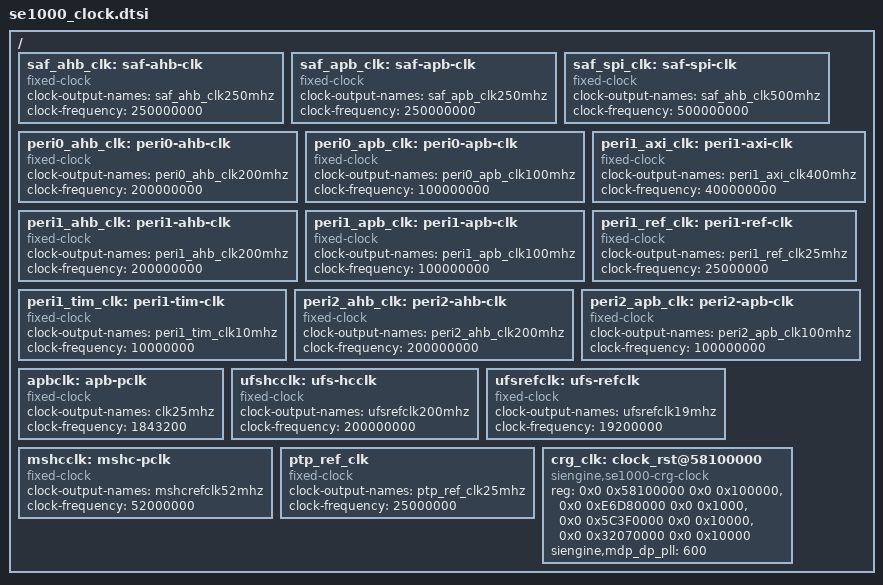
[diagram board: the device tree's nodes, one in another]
/ {
	saf_ahb_clk: saf-ahb-clk {
		clock-output-names = "saf_ahb_clk250mhz";
		clock-frequency = <250000000>;
		#clock-cells = <0x0>;
		compatible = "fixed-clock";
	};

	saf_apb_clk: saf-apb-clk {
		clock-output-names = "saf_apb_clk250mhz";
		clock-frequency = <250000000>;
		#clock-cells = <0x0>;
		compatible = "fixed-clock";
	};

	saf_spi_clk: saf-spi-clk {
		clock-output-names = "saf_ahb_clk500mhz";
		clock-frequency = <500000000>;
		#clock-cells = <0x0>;
		compatible = "fixed-clock";
	};

	peri0_ahb_clk: peri0-ahb-clk {
		clock-output-names = "peri0_ahb_clk200mhz";
		clock-frequency = <200000000>;
		#clock-cells = <0x0>;
		compatible = "fixed-clock";
	};

	peri0_apb_clk: peri0-apb-clk {
		clock-output-names = "peri0_apb_clk100mhz";
		clock-frequency = <100000000>;
		#clock-cells = <0x0>;
		compatible = "fixed-clock";
	};

	peri1_axi_clk: peri1-axi-clk {
		clock-output-names = "peri1_axi_clk400mhz";
		clock-frequency = <400000000>;
		#clock-cells = <0x0>;
		compatible = "fixed-clock";
	};

	peri1_ahb_clk: peri1-ahb-clk {
		clock-output-names = "peri1_ahb_clk200mhz";
		clock-frequency = <200000000>;
		#clock-cells = <0x0>;
		compatible = "fixed-clock";
	};

	peri1_apb_clk: peri1-apb-clk {
		clock-output-names = "peri1_apb_clk100mhz";
		clock-frequency = <100000000>;
		#clock-cells = <0x0>;
		compatible = "fixed-clock";
	};

	peri1_ref_clk: peri1-ref-clk {
		clock-output-names = "peri1_ref_clk25mhz";
		clock-frequency = <25000000>;
		#clock-cells = <0x0>;
		compatible = "fixed-clock";
	};

	peri1_tim_clk: peri1-tim-clk {
		clock-output-names = "peri1_tim_clk10mhz";
		clock-frequency = <10000000>;
		#clock-cells = <0x0>;
		compatible = "fixed-clock";
	};

	peri2_ahb_clk: peri2-ahb-clk {
		clock-output-names = "peri2_ahb_clk200mhz";
		clock-frequency = <200000000>;
		#clock-cells = <0x0>;
		compatible = "fixed-clock";
	};

	peri2_apb_clk: peri2-apb-clk {
		clock-output-names = "peri2_apb_clk100mhz";
		clock-frequency = <100000000>;
		#clock-cells = <0x0>;
		compatible = "fixed-clock";
	};

	apbclk: apb-pclk {
		clock-output-names = "clk25mhz";
		clock-frequency = <1843200>;
		#clock-cells = <0x0>;
		compatible = "fixed-clock";
	};

	ufshcclk: ufs-hcclk {
		clock-output-names = "ufsrefclk200mhz";
		clock-frequency = <200000000>;
		#clock-cells = <0x0>;
		compatible = "fixed-clock";
	};

	ufsrefclk: ufs-refclk {
		clock-output-names = "ufsrefclk19mhz";
		clock-frequency = <19200000>;
		#clock-cells = <0x0>;
		compatible = "fixed-clock";
	};

	mshcclk: mshc-pclk {
		clock-output-names = "mshcrefclk52mhz";
		clock-frequency = <52000000>;
		#clock-cells = <0x0>;
		compatible = "fixed-clock";
	};

	ptp_ref_clk: ptp_ref_clk {
		clock-output-names = "ptp_ref_clk25mhz";
		clock-frequency = <25000000>;
		#clock-cells = <0x0>;
		compatible = "fixed-clock";
	};

	crg_clk: clock_rst@58100000 {
		compatible = "siengine,se1000-crg-clock";
		#clock-cells = <1>;
		#reset-cells = <1>;
		reg = <0x0 0x58100000 0x0 0x100000>,
			<0x0 0xE6D80000 0x0 0x1000>,/* mdp misc*/
			<0x0 0x5C3F0000 0x0 0x10000>,/* aud i2s */
			<0x0 0x32070000 0x0 0x10000>;/* saf_pll */
		siengine,mdp_dp_pll = <600>;
	};
};
